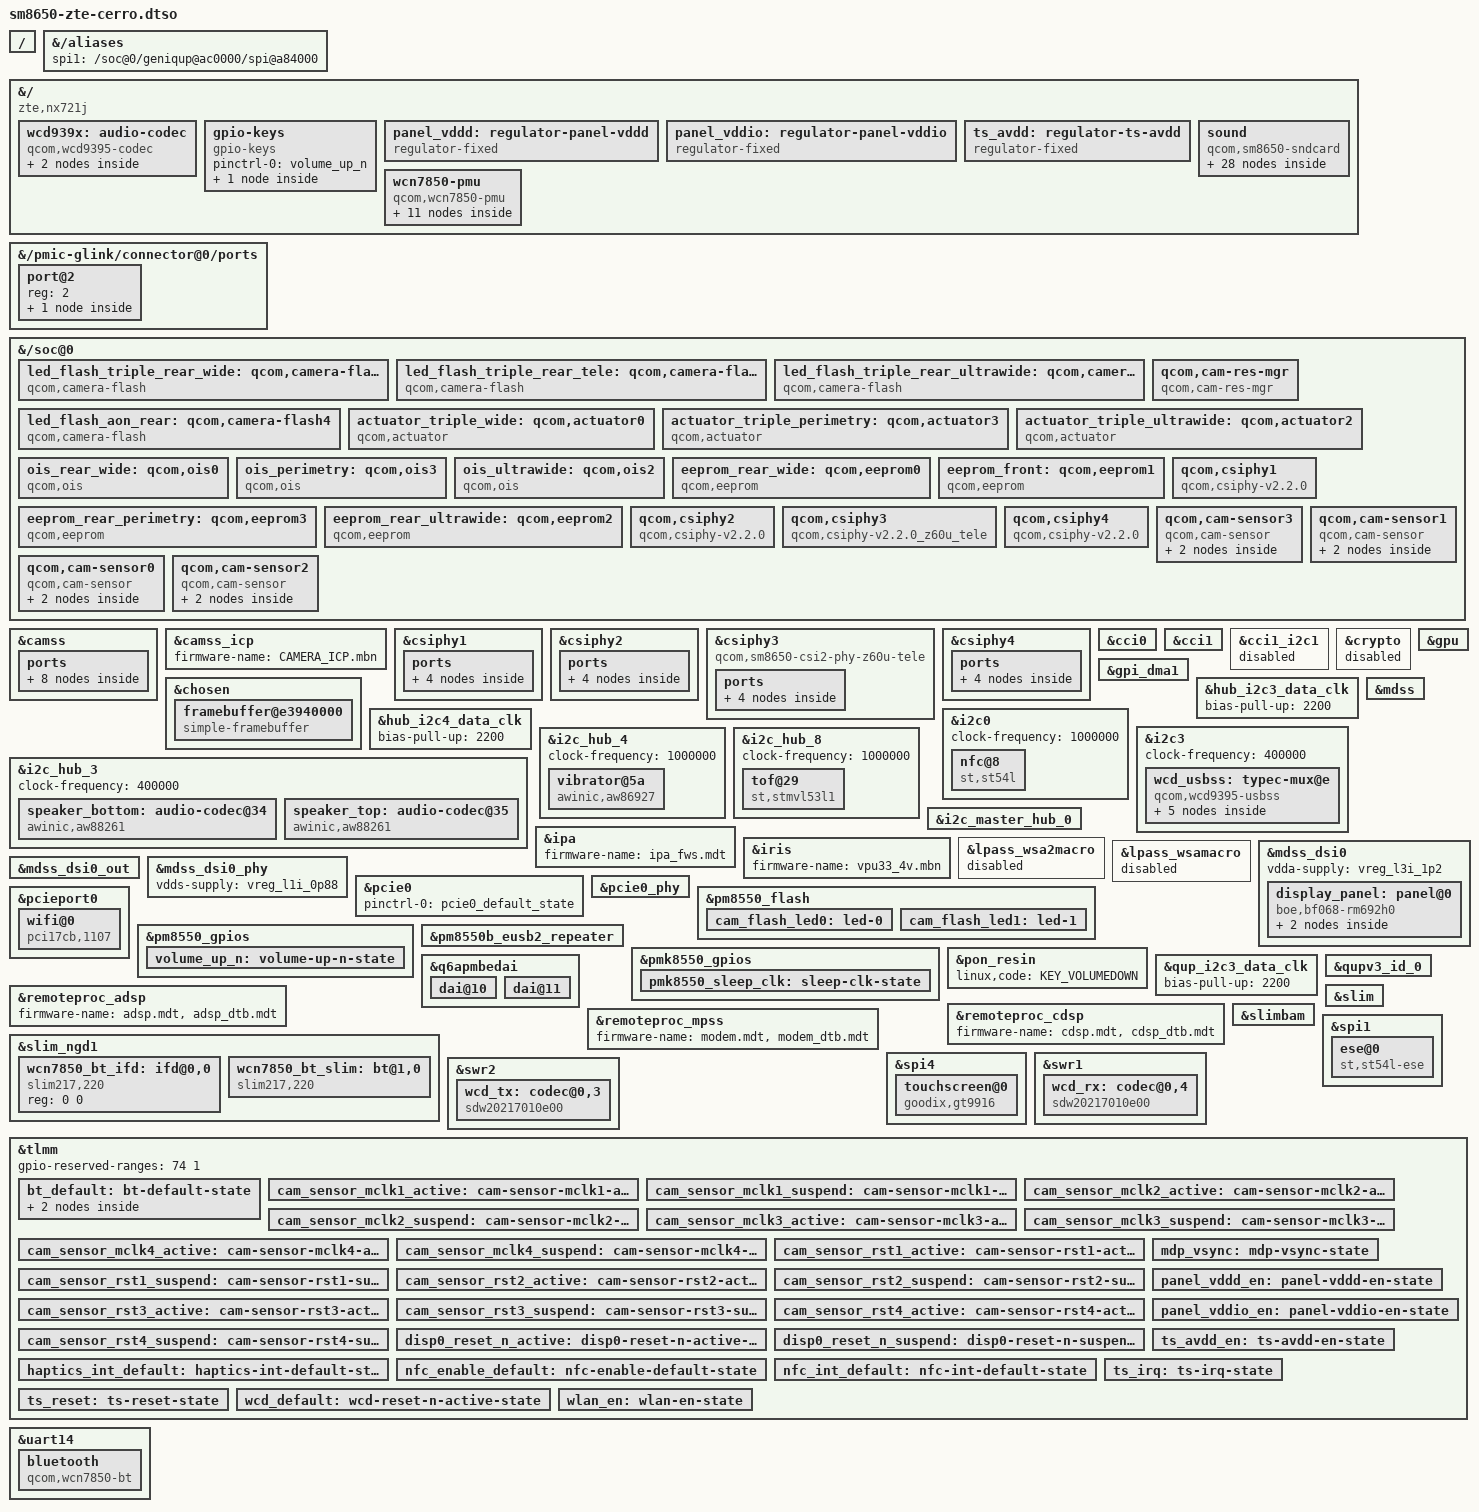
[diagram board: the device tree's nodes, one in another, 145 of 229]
// SPDX-License-Identifier: BSD-3-Clause

/dts-v1/;
/plugin/;

#include <dt-bindings/arm/qcom,ids.h>
#include <dt-bindings/clock/qcom,rpmh.h>
#include <dt-bindings/clock/qcom,sm8650-camcc.h>
#include <dt-bindings/clock/qcom,sm8650-dispcc.h>
#include <dt-bindings/clock/qcom,sm8650-gcc.h>
#include <dt-bindings/gpio/gpio.h>
#include <dt-bindings/input/input.h>
#include <dt-bindings/interrupt-controller/irq.h>
#include <dt-bindings/media/video-interfaces.h>
#include <dt-bindings/leds/common.h>
#include <dt-bindings/msm-camera.h>
#include <dt-bindings/interconnect/qcom,icc.h>
#include <dt-bindings/interconnect/qcom,sm8650-rpmh.h>
#include <dt-bindings/sound/qcom,q6dsp-lpass-ports.h>

/ {
	qcom,msm-id = <QCOM_ID_SM8650 0x20000>, <577 0x20000>;
	qcom,board-id = <8 0>;
};

&{/aliases} {
	spi1 = "/soc@0/geniqup@ac0000/spi@a84000";
};

&{/} {
	model = "ZTE nubia Z60 Ultra";
	compatible = "zte,nx721j", "qcom,sm8650";
	chassis-type = "handset";

	wcd939x: audio-codec {
		compatible = "qcom,wcd9395-codec", "qcom,wcd9390-codec";

		pinctrl-0 = <&wcd_default>;
		pinctrl-names = "default";

		qcom,micbias1-microvolt = <1800000>;
		qcom,micbias2-microvolt = <1800000>;
		qcom,micbias3-microvolt = <1800000>;
		qcom,micbias4-microvolt = <1800000>;
		qcom,mbhc-buttons-vthreshold-microvolt = <100000 200000 400000 500000
							  500000 500000 500000 500000>;
		qcom,mbhc-headset-vthreshold-microvolt = <1700000>;
		qcom,mbhc-headphone-vthreshold-microvolt = <50000>;
		qcom,hphl-jack-type-normally-closed;
		qcom,ground-jack-type-normally-closed;
		qcom,rx-device = <&wcd_rx>;
		qcom,tx-device = <&wcd_tx>;

		reset-gpios = <&tlmm 107 GPIO_ACTIVE_LOW>;

		vdd-buck-supply = <&vreg_l15b_1p8>;
		vdd-rxtx-supply = <&vreg_l15b_1p8>;
		vdd-io-supply = <&vreg_l15b_1p8>;
		vdd-mic-bias-supply = <&vreg_bob1>;
		vdd-px-supply = <&vreg_l3c_1p2>;

		#sound-dai-cells = <1>;

		mode-switch;
		orientation-switch;

		port {
			wcd_codec_headset_in: endpoint {
				remote-endpoint = <&wcd_usbss_headset_out>;
			};
		};
	};

	gpio-keys {
		compatible = "gpio-keys";

		pinctrl-0 = <&volume_up_n>;
		pinctrl-names = "default";

		key-volume-up {
			label = "Volume Up";
			linux,code = <KEY_VOLUMEUP>;
			gpios = <&pm8550_gpios 6 GPIO_ACTIVE_LOW>;
			debounce-interval = <15>;
			linux,can-disable;
			wakeup-source;
		};
	};

	panel_vddd: regulator-panel-vddd {
		compatible = "regulator-fixed";

		regulator-name = "panel_vddd";
		regulator-min-microvolt = <1200000>;
		regulator-max-microvolt = <1200000>;

		gpio = <&tlmm 125 GPIO_ACTIVE_HIGH>;
		enable-active-high;
		regulator-boot-on;

		pinctrl-0 = <&panel_vddd_en>;
		pinctrl-names = "default";
	};

	panel_vddio: regulator-panel-vddio {
		compatible = "regulator-fixed";

		regulator-name = "panel_vddio";
		regulator-min-microvolt = <1800000>;
		regulator-max-microvolt = <1800000>;

		gpio = <&tlmm 14 GPIO_ACTIVE_HIGH>;
		enable-active-high;
		regulator-boot-on;

		vin-supply = <&vreg_l12b_1p8>;

		pinctrl-0 = <&panel_vddio_en>;
		pinctrl-names = "default";
	};

	ts_avdd: regulator-ts-avdd {
		compatible = "regulator-fixed";

		regulator-name = "ts_avdd";

		gpio = <&tlmm 28 GPIO_ACTIVE_HIGH>;
		enable-active-high;

		pinctrl-0 = <&ts_avdd_en>;
		pinctrl-names = "default";
	};

	sound {
		compatible = "qcom,sm8650-sndcard", "qcom,sm8450-sndcard";
		model = "SM8650-CERRO";
		audio-routing = "IN1_HPHL", "HPHL_OUT",
				"IN2_HPHR", "HPHR_OUT",
				"AMIC1", "MIC BIAS1",
				"AMIC2", "MIC BIAS2",
				"AMIC3", "MIC BIAS3",
				"AMIC4", "MIC BIAS3",
				"AMIC5", "MIC BIAS4",
				"TX SWR_INPUT0", "ADC1_OUTPUT",
				"TX SWR_INPUT1", "ADC2_OUTPUT",
				"TX SWR_INPUT2", "ADC3_OUTPUT",
				"TX SWR_INPUT3", "ADC4_OUTPUT",
				"VA SWR_MIC0", "ADC1_OUTPUT",
				"VA SWR_MIC1", "ADC2_OUTPUT",
				"VA SWR_MIC2", "ADC3_OUTPUT",
				"VA SWR_MIC3", "ADC4_OUTPUT";

		pinctrl-0 = <&i2s0_default_state>;
		pinctrl-names = "default";

		speaker-playback-dai-link {
			link-name = "Speaker Playback";

			cpu {
				sound-dai = <&q6apmbedai PRIMARY_MI2S_RX>;
			};

			codec {
				sound-dai = <&speaker_top>, <&speaker_bottom>;
			};

			platform {
				sound-dai = <&q6apm>;
			};
		};

		speaker-feedback-dai-link {
			link-name = "Speaker Feedback";

			cpu {
				sound-dai = <&q6apmbedai PRIMARY_MI2S_TX>;
			};

			codec {
				sound-dai = <&speaker_top>, <&speaker_bottom>;
			};

			platform {
				sound-dai = <&q6apm>;
			};
		};

		wcd-playback-dai-link {
			link-name = "WCD Playback";

			cpu {
				sound-dai = <&q6apmbedai RX_CODEC_DMA_RX_0>;
			};

			codec {
				sound-dai = <&wcd939x 0>, <&swr1 0>, <&lpass_rxmacro 0>;
			};

			platform {
				sound-dai = <&q6apm>;
			};
		};

		wcd-capture-dai-link {
			link-name = "WCD Capture";

			cpu {
				sound-dai = <&q6apmbedai TX_CODEC_DMA_TX_3>;
			};

			codec {
				sound-dai = <&wcd939x 1>, <&swr2 1>, <&lpass_txmacro 0>;
			};

			platform {
				sound-dai = <&q6apm>;
			};
		};

		bt-playback-dai-link {
			link-name = "BT Playback";

			cpu {
				sound-dai = <&q6apmbedai SLIMBUS_6_RX>;
			};

			codec {
				sound-dai = <&wcn7850_bt_slim 0>;
			};

			platform {
				sound-dai = <&q6apm>;
			};
		};

		bt-capture-dai-link {
			link-name = "BT Capture";

			cpu {
				sound-dai = <&q6apmbedai SLIMBUS_6_TX>;
			};

			codec {
				sound-dai = <&wcn7850_bt_slim 1>;
			};

			platform {
				sound-dai = <&q6apm>;
			};
		};

		va-capture-dai-link {
			link-name = "VA Capture";

			cpu {
				sound-dai = <&q6apmbedai VA_CODEC_DMA_TX_0>;
			};

			codec {
				sound-dai = <&wcd939x 1>, <&swr2 1>, <&lpass_vamacro 0>;
			};

			platform {
				sound-dai = <&q6apm>;
			};
		};
	};

	wcn7850-pmu {
		compatible = "qcom,wcn7850-pmu";

		pinctrl-0 = <&wlan_en>, <&bt_default>, <&pmk8550_sleep_clk>;
		pinctrl-names = "default";

		wlan-enable-gpios = <&tlmm 16 GPIO_ACTIVE_HIGH>;
		bt-enable-gpios = <&tlmm 17 GPIO_ACTIVE_HIGH>;

		vdd-supply = <&vreg_s4i_0p85>;
		vddio-supply = <&vreg_l15b_1p8>;
		vddio1p2-supply = <&vreg_l3c_1p2>;
		vddaon-supply = <&vreg_s2c_0p8>;
		vdddig-supply = <&vreg_s3c_0p9>;
		vddrfa1p2-supply = <&vreg_s1c_1p2>;
		vddrfa1p8-supply = <&vreg_s6c_1p8>;

		clocks = <&rpmhcc RPMH_RF_CLK1>;

		regulators {
			vreg_pmu_rfa_cmn: ldo0 {
				regulator-name = "vreg_pmu_rfa_cmn";
			};

			vreg_pmu_aon_0p59: ldo1 {
				regulator-name = "vreg_pmu_aon_0p59";
			};

			vreg_pmu_wlcx_0p8: ldo2 {
				regulator-name = "vreg_pmu_wlcx_0p8";
			};

			vreg_pmu_wlmx_0p85: ldo3 {
				regulator-name = "vreg_pmu_wlmx_0p85";
			};

			vreg_pmu_btcmx_0p85: ldo4 {
				regulator-name = "vreg_pmu_btcmx_0p85";
			};

			vreg_pmu_rfa_0p8: ldo5 {
				regulator-name = "vreg_pmu_rfa_0p8";
			};

			vreg_pmu_rfa_1p2: ldo6 {
				regulator-name = "vreg_pmu_rfa_1p2";
			};

			vreg_pmu_rfa_1p8: ldo7 {
				regulator-name = "vreg_pmu_rfa_1p8";
			};

			vreg_pmu_pcie_0p9: ldo8 {
				regulator-name = "vreg_pmu_pcie_0p9";
			};

			vreg_pmu_pcie_1p8: ldo9 {
				regulator-name = "vreg_pmu_pcie_1p8";
			};
		};
	};
};

&{/pmic-glink/connector@0/ports} {
	#address-cells = <1>;
	#size-cells = <0>;

	port@2 {
		reg = <2>;

		pmic_glink_sbu: endpoint {
			remote-endpoint = <&wcd_usbss_sbu_mux>;
		};
	};
};

&{/soc@0} {
	led_flash_triple_rear_wide: qcom,camera-flash1 {
		cell-index = <1>;
		compatible = "qcom,camera-flash";
		flash-source = <&cam_flash_led0 &cam_flash_led1>;
		torch-source = <&cam_flash_led0 &cam_flash_led1>;
		leds = <&cam_flash_led0 &cam_flash_led1
			&cam_flash_led0 &cam_flash_led1>;
		led-names = "flash0", "flash1", "torch0", "torch1";
	};

	led_flash_triple_rear_tele: qcom,camera-flash2 {
		cell-index = <2>;
		compatible = "qcom,camera-flash";
		flash-source = <&cam_flash_led0 &cam_flash_led1>;
		torch-source = <&cam_flash_led0 &cam_flash_led1>;
		leds = <&cam_flash_led0 &cam_flash_led1
			&cam_flash_led0 &cam_flash_led1>;
		led-names = "flash0", "flash1", "torch0", "torch1";
	};

	led_flash_triple_rear_ultrawide: qcom,camera-flash3 {
		cell-index = <3>;
		compatible = "qcom,camera-flash";
		flash-source = <&cam_flash_led0 &cam_flash_led1>;
		torch-source = <&cam_flash_led0 &cam_flash_led1>;
		leds = <&cam_flash_led0 &cam_flash_led1
			&cam_flash_led0 &cam_flash_led1>;
		led-names = "flash0", "flash1", "torch0", "torch1";
	};

	led_flash_aon_rear: qcom,camera-flash4 {
		cell-index = <4>;
		compatible = "qcom,camera-flash";
		flash-source = <&cam_flash_led0 &cam_flash_led1>;
		torch-source = <&cam_flash_led0 &cam_flash_led1>;
		leds = <&cam_flash_led0 &cam_flash_led1
			&cam_flash_led0 &cam_flash_led1>;
		led-names = "flash0", "flash1", "torch0", "torch1";
	};

	qcom,cam-res-mgr {
		compatible = "qcom,cam-res-mgr";
	};

	actuator_triple_wide: qcom,actuator0 {
		cell-index = <0>;
		compatible = "qcom,actuator";
		cci-master = <CCI_MASTER_1>;
		cci-i2c-bus = <&cci0_i2c1>;
		cam_vaf-supply = <&vreg_l3m_2p8>;
		regulator-names = "cam_vaf";
		rgltr-cntrl-support;
		rgltr-min-voltage = <2704000>;
		rgltr-max-voltage = <3000000>;
		rgltr-load-current = <103000>;
	};

	actuator_triple_perimetry: qcom,actuator3 {
		cell-index = <3>;
		compatible = "qcom,actuator";
		cci-master = <CCI_MASTER_0>;
		cci-i2c-bus = <&cci0_i2c0>;
		cam_vaf-supply = <&vreg_l4m_2p8>;
		cam_v_custom1-supply = <&vreg_l6m_2p8>;
		regulator-names = "cam_vaf", "cam_v_custom1";
		rgltr-cntrl-support;
		rgltr-min-voltage = <2800000 2800000>;
		rgltr-max-voltage = <2800000 2800000>;
		rgltr-load-current = <103000 103000>;
	};

	actuator_triple_ultrawide: qcom,actuator2 {
		cell-index = <2>;
		compatible = "qcom,actuator";
		cci-master = <CCI_MASTER_0>;
		cci-i2c-bus = <&cci1_i2c0>;
		cam_vaf-supply = <&vreg_bob2>;
		regulator-names = "cam_vaf";
		rgltr-cntrl-support;
		rgltr-min-voltage = <2704000>;
		rgltr-max-voltage = <3000000>;
		rgltr-load-current = <103000>;
	};

	ois_rear_wide: qcom,ois0 {
		cell-index = <0>;
		compatible = "qcom,ois";
		cci-master = <CCI_MASTER_1>;
		cci-i2c-bus = <&cci0_i2c1>;
		cam_vaf-supply = <&vreg_l3m_2p8>;
		cam_v_custom1-supply = <&vreg_l7m_2p96>;
		regulator-names = "cam_vaf", "cam_v_custom1";
		rgltr-cntrl-support;
		rgltr-min-voltage = <2704000 2960000>;
		rgltr-max-voltage = <3000000 2960000>;
		rgltr-load-current = <103000 90000>;
	};

	ois_perimetry: qcom,ois3 {
		cell-index = <3>;
		compatible = "qcom,ois";
		cci-master = <CCI_MASTER_0>;
		cci-i2c-bus = <&cci0_i2c0>;
		cam_vaf-supply = <&vreg_l4m_2p8>;
		cam_v_custom1-supply = <&vreg_l6m_2p8>;
		regulator-names = "cam_vaf", "cam_v_custom1";
		rgltr-cntrl-support;
		rgltr-min-voltage = <2800000 2800000>;
		rgltr-max-voltage = <2800000 2800000>;
		rgltr-load-current = <119000 119000>;
	};

	ois_ultrawide: qcom,ois2 {
		cell-index = <2>;
		compatible = "qcom,ois";
		cci-master = <CCI_MASTER_0>;
		cci-i2c-bus = <&cci1_i2c0>;
		cam_vio-supply = <&vreg_l5m_1p8>;
		cam_vaf-supply = <&vreg_bob2>;
		regulator-names = "cam_vio", "cam_vaf";
		rgltr-cntrl-support;
		rgltr-min-voltage = <1800000 2704000>;
		rgltr-max-voltage = <1800000 3000000>;
		rgltr-load-current = <4000 103000>;
	};

	eeprom_rear_wide: qcom,eeprom0 {
		cell-index = <0>;
		compatible = "qcom,eeprom";
		cam_vio-supply = <&vreg_l5m_1p8>;
		cam_vdig-supply = <&vreg_l1m_1p1>;
		cam_vaf-supply = <&vreg_l3m_2p8>;
		cam_v_custom1-supply = <&vreg_l7m_2p96>;
		regulator-names = "cam_vio", "cam_vdig", "cam_vaf", "cam_v_custom1";
		rgltr-cntrl-support;
		rgltr-min-voltage = <1800000 1104000 2704000 2960000>;
		rgltr-max-voltage = <1800000 1104000 3000000 2960000>;
		rgltr-load-current = <3500 140000 103000 90000>;
		gpio-no-mux = <0>;
		pinctrl-names = "cam_default", "cam_suspend";
		pinctrl-0 = <&cam_sensor_mclk1_active
			     &cam_sensor_rst1_active>;
		pinctrl-1 = <&cam_sensor_mclk1_suspend
			     &cam_sensor_rst1_suspend>;
		gpios = <&tlmm 101 0>,
			<&tlmm 15 0>,
			<&tlmm 13 0>;
		gpio-reset = <1>;
		gpio-custom1 = <2>;
		gpio-req-tbl-num = <0 1 2>;
		gpio-req-tbl-flags = <1 0 0>;
		gpio-req-tbl-label = "CAMIF_MCLK1",
				     "CAM_RESET1",
				     "CAM_VANA1";
		cci-master = <CCI_MASTER_1>;
		cci-i2c-bus = <&cci0_i2c1>;
		clocks = <&camcc CAM_CC_MCLK1_CLK>;
		clock-names = "cam_clk";
		clock-cntl-level = "nominal";
		clock-rates = <24000000>;
		power-domains = <&camcc CAM_CC_TITAN_TOP_GDSC>;
	};

	eeprom_front: qcom,eeprom1 {
		cell-index = <1>;
		compatible = "qcom,eeprom";
		cam_vio-supply = <&vreg_l5m_1p8>;
		regulator-names = "cam_vio";
		rgltr-cntrl-support;
		rgltr-min-voltage = <1800000>;
		rgltr-max-voltage = <1800000>;
		rgltr-load-current = <6000>;
		gpio-no-mux = <0>;
		pinctrl-names = "cam_default", "cam_suspend";
		pinctrl-0 = <&cam_sensor_mclk4_active
			     &cam_sensor_rst4_active>;
		pinctrl-1 = <&cam_sensor_mclk4_suspend
			     &cam_sensor_rst4_suspend>;
		gpios = <&tlmm 104 0>,
			<&tlmm 7 0>,
			<&tlmm 58 0>;
		gpio-reset = <1>;
		gpio-custom1 = <2>;
		gpio-req-tbl-num = <0 1 2>;
		gpio-req-tbl-flags = <1 0 0>;
		gpio-req-tbl-label = "CAMIF_MCLK4",
				     "CAM_RESET4",
				     "CAM_VANA4";
		cci-master = <CCI_MASTER_0>;
		cci-i2c-bus = <&cci0_i2c0>;
		clocks = <&camcc CAM_CC_MCLK4_CLK>;
		clock-names = "cam_clk";
		clock-cntl-level = "nominal";
		clock-rates = <24000000>;
		power-domains = <&camcc CAM_CC_TITAN_TOP_GDSC>;
	};

	eeprom_rear_perimetry: qcom,eeprom3 {
		cell-index = <3>;
		compatible = "qcom,eeprom";
		cam_vio-supply = <&vreg_l5m_1p8>;
		cam_vaf-supply = <&vreg_l4m_2p8>;
		cam_v_custom1-supply = <&vreg_l6m_2p8>;
		regulator-names = "cam_vio", "cam_vaf", "cam_v_custom1";
		rgltr-cntrl-support;
		rgltr-min-voltage = <1800000 2704000 2800000>;
		rgltr-max-voltage = <1800000 3000000 2800000>;
		rgltr-load-current = <6000 103000 119000>;
		gpio-no-mux = <0>;
		pinctrl-names = "cam_default", "cam_suspend";
		pinctrl-0 = <&cam_sensor_mclk3_active
			     &cam_sensor_rst3_active>;
		pinctrl-1 = <&cam_sensor_mclk3_suspend
			     &cam_sensor_rst3_suspend>;
		gpios = <&tlmm 103 0>,
			<&tlmm 109 0>,
			<&tlmm 6 0>;
		gpio-reset = <1>;
		gpio-custom1 = <2>;
		gpio-req-tbl-num = <0 1 2>;
		gpio-req-tbl-flags = <1 0 0>;
		gpio-req-tbl-label = "CAMIF_MCLK3",
				     "CAM_RESET3",
				     "CAM_VANA3";
		cci-master = <CCI_MASTER_0>;
		cci-i2c-bus = <&cci0_i2c0>;
		clocks = <&camcc CAM_CC_MCLK3_CLK>;
		clock-names = "cam_clk";
		clock-cntl-level = "nominal";
		clock-rates = <24000000>;
		power-domains = <&camcc CAM_CC_TITAN_TOP_GDSC>;
	};

	eeprom_rear_ultrawide: qcom,eeprom2 {
		cell-index = <2>;
		compatible = "qcom,eeprom";
		cam_vio-supply = <&vreg_l5m_1p8>;
		regulator-names = "cam_vio";
		rgltr-cntrl-support;
		rgltr-min-voltage = <1800000>;
		rgltr-max-voltage = <1800000>;
		rgltr-load-current = <3500>;
		gpio-no-mux = <0>;
		pinctrl-names = "cam_default", "cam_suspend";
		pinctrl-0 = <&cam_sensor_mclk2_active
			     &cam_sensor_rst2_active>;
		pinctrl-1 = <&cam_sensor_mclk2_suspend
			     &cam_sensor_rst2_suspend>;
		gpios = <&tlmm 102 0>,
			<&tlmm 3 0>,
			<&tlmm 2 0>;
		gpio-reset = <1>;
		gpio-custom1 = <2>;
		gpio-req-tbl-num = <0 1 2>;
		gpio-req-tbl-flags = <1 0 0>;
		gpio-req-tbl-label = "CAMIF_MCLK2",
				     "CAM_RESET2",
				     "CAM_VANA2";
		cci-master = <CCI_MASTER_0>;
		cci-i2c-bus = <&cci1_i2c0>;
		clocks = <&camcc CAM_CC_MCLK2_CLK>;
		clock-names = "cam_clk";
		clock-cntl-level = "nominal";
		clock-rates = <24000000>;
		power-domains = <&camcc CAM_CC_TITAN_TOP_GDSC>;
	};

	qcom,csiphy1 {
		cell-index = <1>;
		compatible = "qcom,csiphy-v2.2.0", "qcom,csiphy";
		phys = <&csiphy1>;
	};

	qcom,csiphy2 {
		cell-index = <2>;
		compatible = "qcom,csiphy-v2.2.0", "qcom,csiphy";
		phys = <&csiphy2>;
	};

	qcom,csiphy3 {
		cell-index = <3>;
		compatible = "qcom,csiphy-v2.2.0_z60u_tele", "qcom,csiphy";
		phys = <&csiphy3>;
	};

	qcom,csiphy4 {
		cell-index = <4>;
		compatible = "qcom,csiphy-v2.2.0", "qcom,csiphy";
		phys = <&csiphy4>;
	};

	qcom,cam-sensor3 {
		cell-index = <3>;
		compatible = "qcom,cam-sensor";
		csiphy-sd-index = <3>;
		sensor-position-roll = <90>;
		sensor-position-pitch = <0>;
		sensor-position-yaw = <180>;
		actuator-src = <&actuator_triple_perimetry>;
		eeprom-src = <&eeprom_rear_perimetry>;
		led-flash-src = <&led_flash_triple_rear_tele>;
		ois-src = <&ois_perimetry>;
		cam_vio-supply = <&vreg_l5m_1p8>;
		cam_vaf-supply = <&vreg_l4m_2p8>;
		cam_v_custom1-supply = <&vreg_l6m_2p8>;
		regulator-names = "cam_vio", "cam_vaf", "cam_v_custom1";
		rgltr-cntrl-support;
		rgltr-min-voltage = <1800000 2704000 2800000>;
		rgltr-max-voltage = <1800000 3000000 2800000>;
		rgltr-load-current = <6000 103000 119000>;
		gpio-no-mux = <0>;
		pinctrl-names = "cam_default", "cam_suspend";
		pinctrl-0 = <&cam_sensor_mclk3_active
			     &cam_sensor_rst3_active>;
		pinctrl-1 = <&cam_sensor_mclk3_suspend
			     &cam_sensor_rst3_suspend>;
		gpios = <&tlmm 103 0>,
			<&tlmm 109 0>,
			<&tlmm 6 0>;
		gpio-reset = <1>;
		gpio-custom1 = <2>;
		gpio-req-tbl-num = <0 1 2>;
		gpio-req-tbl-flags = <1 0 0>;
		gpio-req-tbl-label = "CAMIF_MCLK3",
				     "CAM_RESET3",
				     "CAM_VANA3";
		cci-master = <CCI_MASTER_0>;
		cci-i2c-bus = <&cci0_i2c0>;
		clocks = <&camcc CAM_CC_MCLK3_CLK>;
		clock-names = "cam_clk";
		clock-cntl-level = "nominal";
		clock-rates = <24000000>;
		power-domains = <&camcc CAM_CC_TITAN_TOP_GDSC>;
		zte-tof-enable;

		port {
			sensor3_ep: endpoint {
				remote-endpoint = <&csiphy3_in>;
			};
		};
	};

	qcom,cam-sensor1 {
		cell-index = <1>;
		compatible = "qcom,cam-sensor";
		csiphy-sd-index = <4>;
		sensor-position-roll = <270>;
		sensor-position-pitch = <0>;
		sensor-position-yaw = <0>;
		eeprom-src = <&eeprom_front>;
		cam_vio-supply = <&vreg_l5m_1p8>;
		regulator-names = "cam_vio";
		rgltr-cntrl-support;
		rgltr-min-voltage = <1800000>;
		rgltr-max-voltage = <1800000>;
		rgltr-load-current = <6000>;
		gpio-no-mux = <0>;
		pinctrl-names = "cam_default", "cam_suspend";
		pinctrl-0 = <&cam_sensor_mclk4_active
			     &cam_sensor_rst4_active>;
		pinctrl-1 = <&cam_sensor_mclk4_suspend
			     &cam_sensor_rst4_suspend>;
		gpios = <&tlmm 104 0>,
			<&tlmm 7 0>,
			<&tlmm 58 0>;
		gpio-reset = <1>;
		gpio-custom1 = <2>;
		gpio-req-tbl-num = <0 1 2>;
		gpio-req-tbl-flags = <1 0 0>;
		gpio-req-tbl-label = "CAMIF_MCLK4",
				     "CAM_RESET4",
				     "CAM_VANA4";
		cci-master = <CCI_MASTER_0>;
		cci-i2c-bus = <&cci0_i2c0>;
		clocks = <&camcc CAM_CC_MCLK4_CLK>;
		clock-names = "cam_clk";
		clock-cntl-level = "nominal";
		clock-rates = <24000000>;
		power-domains = <&camcc CAM_CC_TITAN_TOP_GDSC>;
		zte-tof-enable;

		port {
			sensor1_ep: endpoint {
				remote-endpoint = <&csiphy4_in>;
			};
		};
	};

	qcom,cam-sensor0 {
		cell-index = <0>;
		compatible = "qcom,cam-sensor";
		csiphy-sd-index = <1>;
		sensor-position-roll = <90>;
		sensor-position-pitch = <0>;
		sensor-position-yaw = <180>;
		actuator-src = <&actuator_triple_wide>;
		ois-src = <&ois_rear_wide>;
		eeprom-src = <&eeprom_rear_wide>;
		led-flash-src = <&led_flash_triple_rear_wide>;
		cam_vio-supply = <&vreg_l5m_1p8>;
		cam_vdig-supply = <&vreg_l1m_1p1>;
		cam_vaf-supply = <&vreg_l3m_2p8>;
		cam_v_custom1-supply = <&vreg_l7m_2p96>;
		regulator-names = "cam_vio", "cam_vdig", "cam_vaf", "cam_v_custom1";
		rgltr-cntrl-support;
		rgltr-min-voltage = <1800000 1104000 2704000 2960000>;
		rgltr-max-voltage = <1800000 1104000 3000000 2960000>;
		rgltr-load-current = <3500 140000 103000 90000>;
		gpio-no-mux = <0>;
		pinctrl-names = "cam_default", "cam_suspend";
		pinctrl-0 = <&cam_sensor_mclk1_active
			     &cam_sensor_rst1_active>;
		pinctrl-1 = <&cam_sensor_mclk1_suspend
			     &cam_sensor_rst1_suspend>;
		gpios = <&tlmm 101 0>,
			<&tlmm 15 0>,
			<&tlmm 13 0>;
		gpio-reset = <1>;
		gpio-custom1 = <2>;
		gpio-req-tbl-num = <0 1 2>;
		gpio-req-tbl-flags = <1 0 0>;
		gpio-req-tbl-label = "CAMIF_MCLK1",
				     "CAM_RESET1",
				     "CAM_VANA1";
		cci-master = <CCI_MASTER_1>;
		cci-i2c-bus = <&cci0_i2c1>;
		clocks = <&camcc CAM_CC_MCLK1_CLK>;
		clock-names = "cam_clk";
		clock-cntl-level = "nominal";
		clock-rates = <24000000>;
		power-domains = <&camcc CAM_CC_TITAN_TOP_GDSC>;
		zte-tof-enable;

		port {
			sensor0_ep: endpoint {
				remote-endpoint = <&csiphy1_in>;
			};
		};
	};

	qcom,cam-sensor2 {
		cell-index = <2>;
		compatible = "qcom,cam-sensor";
		csiphy-sd-index = <2>;
		sensor-position-roll = <90>;
		sensor-position-pitch = <0>;
		sensor-position-yaw = <180>;
		actuator-src = <&actuator_triple_ultrawide>;
		eeprom-src = <&eeprom_rear_ultrawide>;
		led-flash-src = <&led_flash_triple_rear_ultrawide>;
		ois-src = <&ois_ultrawide>;
		cam_vio-supply = <&vreg_l5m_1p8>;
		cam_vdig-supply = <&vreg_l2m_1p056>;
		regulator-names = "cam_vio", "cam_vdig";
		rgltr-cntrl-support;
		rgltr-min-voltage = <1800000 1056000>;
		rgltr-max-voltage = <1800000 1056000>;
		rgltr-load-current = <3500 140000>;
		gpio-no-mux = <0>;
		pinctrl-names = "cam_default", "cam_suspend";
		pinctrl-0 = <&cam_sensor_mclk2_active
			     &cam_sensor_rst2_active>;
		pinctrl-1 = <&cam_sensor_mclk2_suspend
			     &cam_sensor_rst2_suspend>;
		gpios = <&tlmm 102 0>,
			<&tlmm 3 0>,
			<&tlmm 2 0>;
		gpio-reset = <1>;
		gpio-custom1 = <2>;
		gpio-req-tbl-num = <0 1 2>;
		gpio-req-tbl-flags = <1 0 0>;
		gpio-req-tbl-label = "CAMIF_MCLK2",
				     "CAM_RESET2",
				     "CAM_VANA2";
		cci-master = <CCI_MASTER_0>;
		cci-i2c-bus = <&cci1_i2c0>;
		clocks = <&camcc CAM_CC_MCLK2_CLK>;
		clock-names = "cam_clk";
		clock-cntl-level = "nominal";
		clock-rates = <24000000>;
		power-domains = <&camcc CAM_CC_TITAN_TOP_GDSC>;
		zte-tof-enable;

		port {
			sensor2_ep: endpoint {
				remote-endpoint = <&csiphy2_in>;
			};
		};
	};
};

&camss {
	vdd-csiphy01-0p9-supply = <&vreg_l2i_0p88>;
	vdd-csiphy01-1p2-supply = <&vreg_l3i_1p2>;
	vdd-csiphy24-0p9-supply = <&vreg_l2i_0p88>;
	vdd-csiphy24-1p2-supply = <&vreg_l3i_1p2>;
	vdd-csiphy35-0p9-supply = <&vreg_l2i_0p88>;
	vdd-csiphy35-1p2-supply = <&vreg_l3i_1p2>;

	status = "okay";

	ports {
		#address-cells = <1>;
		#size-cells = <0>;

		port@1 {
			camss_ep1: endpoint {
				bus-type = <MEDIA_BUS_TYPE_CSI2_CPHY>;
				data-lanes = <1 2 3>;
				remote-endpoint = <&csiphy1_out>;
			};
		};

		port@2 {
			camss_ep2: endpoint {
				bus-type = <MEDIA_BUS_TYPE_CSI2_CPHY>;
				data-lanes = <1 2 3>;
				remote-endpoint = <&csiphy2_out>;
			};
		};

		port@3 {
			camss_ep3: endpoint {
				bus-type = <MEDIA_BUS_TYPE_CSI2_CPHY>;
				data-lanes = <1 2 3>;
				remote-endpoint = <&csiphy3_out>;
			};
		};

		port@4 {
			camss_ep4: endpoint {
				bus-type = <MEDIA_BUS_TYPE_CSI2_DPHY>;
				data-lanes = <1 2 3 4>;
				remote-endpoint = <&csiphy4_out>;
			};
		};
	};
};

&camss_icp {
	firmware-name = "CAMERA_ICP.mbn";

	status = "okay";
};

&csiphy1 {
	vdda-phy-supply = <&vreg_l2i_0p88>;
	vdda-pll-supply = <&vreg_l3i_1p2>;

	status = "okay";

	ports {
		port@0 {
			csiphy1_in: endpoint {
				bus-type = <MEDIA_BUS_TYPE_CSI2_CPHY>;
				data-lanes = <1 2 3>;
				remote-endpoint = <&sensor0_ep>;
			};
		};

		port@1 {
			csiphy1_out: endpoint {
				remote-endpoint = <&camss_ep1>;
			};
		};
	};
};

&csiphy2 {
	vdda-phy-supply = <&vreg_l2i_0p88>;
	vdda-pll-supply = <&vreg_l3i_1p2>;

	status = "okay";

	ports {
		port@0 {
			csiphy2_in: endpoint {
				bus-type = <MEDIA_BUS_TYPE_CSI2_CPHY>;
				data-lanes = <1 2 3>;
				remote-endpoint = <&sensor2_ep>;
			};
		};

		port@1 {
			csiphy2_out: endpoint {
				remote-endpoint = <&camss_ep2>;
			};
		};
	};
};

&csiphy3 {
	compatible = "qcom,sm8650-csi2-phy-z60u-tele";
	vdda-phy-supply = <&vreg_l2i_0p88>;
	vdda-pll-supply = <&vreg_l3i_1p2>;

	status = "okay";

	ports {
		port@0 {
			csiphy3_in: endpoint {
				bus-type = <MEDIA_BUS_TYPE_CSI2_CPHY>;
				data-lanes = <1 2 3>;
				remote-endpoint = <&sensor3_ep>;
			};
		};

		port@1 {
			csiphy3_out: endpoint {
				remote-endpoint = <&camss_ep3>;
			};
		};
	};
};

&csiphy4 {
	vdda-phy-supply = <&vreg_l2i_0p88>;
	vdda-pll-supply = <&vreg_l3i_1p2>;

	status = "okay";

	ports {
		port@0 {
			csiphy4_in: endpoint {
				bus-type = <MEDIA_BUS_TYPE_CSI2_DPHY>;
				data-lanes = <1 2 3 4>;
				remote-endpoint = <&sensor1_ep>;
			};
		};

		port@1 {
			csiphy4_out: endpoint {
				remote-endpoint = <&camss_ep4>;
			};
		};
	};
};

&cci0 {
	status = "okay";
};

&cci1 {
	/* Master 1 pins carry the main camera VANA enable (gpio13) */
	pinctrl-0 = <&cci1_0_default>;
	pinctrl-1 = <&cci1_0_sleep>;

	status = "okay";
};

&cci1_i2c1 {
	status = "disabled";
};

&chosen {
	#address-cells = <2>;
	#size-cells = <2>;

	framebuffer@e3940000 {
		compatible = "simple-framebuffer";
		reg = <0x0 0xe3940000 0x0 0x2b00000>;
		width = <1116>;
		height = <2480>;
		stride = <(1116 * 4)>;
		format = "a8b8g8r8";
		interconnects = <&mmss_noc MASTER_MDP QCOM_ICC_TAG_ALWAYS
				 &mc_virt SLAVE_EBI1 QCOM_ICC_TAG_ALWAYS>;
		clocks = <&gcc GCC_DISP_HF_AXI_CLK>;
		power-domains = <&dispcc MDSS_GDSC>;

		vci-supply = <&vreg_l13b_3p0>;
		vdd-supply = <&vreg_l11b_1p2>;
		vddd-supply = <&panel_vddd>;
		vddio-supply = <&panel_vddio>;
	};
};

&crypto {
	status = "disabled";
};

&gpi_dma1 {
	status = "okay";
};

&gpu {
	status = "okay";
};

&hub_i2c3_data_clk {
	/* Use internal I2C pull-up */
	bias-pull-up = <2200>;
};

&hub_i2c4_data_clk {
	/* Use internal I2C pull-up */
	bias-pull-up = <2200>;
};

&i2c0 {
	#address-cells = <1>;
	#size-cells = <0>;

	clock-frequency = <1000000>;

	status = "okay";

	nfc@8 {
		compatible = "st,st54l", "st,st21nfcd";
		reg = <0x08>;

		interrupts-extended = <&tlmm 75 IRQ_TYPE_LEVEL_HIGH>;
		reset-gpios = <&tlmm 34 GPIO_ACTIVE_HIGH>;
		ese-power-gpios = <&tlmm 46 GPIO_ACTIVE_HIGH>;

		pinctrl-0 = <&nfc_int_default>, <&nfc_enable_default>;
		pinctrl-names = "default";

		wakeup-source;
	};
};

&i2c3 {
	#address-cells = <1>;
	#size-cells = <0>;

	clock-frequency = <400000>;

	status = "okay";

	wcd_usbss: typec-mux@e {
		compatible = "qcom,wcd9395-usbss", "qcom,wcd9390-usbss";
		reg = <0xe>;

		vdd-supply = <&vreg_l15b_1p8>;

		mode-switch;
		orientation-switch;

		ports {
			#address-cells = <1>;
			#size-cells = <0>;

			port@0 {
				reg = <0>;

				wcd_usbss_sbu_mux: endpoint {
					remote-endpoint = <&pmic_glink_sbu>;
				};
			};

			port@1 {
				reg = <1>;

				wcd_usbss_headset_out: endpoint {
					remote-endpoint = <&wcd_codec_headset_in>;
				};
			};
		};
	};
};

&i2c_hub_3 {
	#address-cells = <1>;
	#size-cells = <0>;

	clock-frequency = <400000>;

	status = "okay";

	/* Bottom speaker */
	speaker_bottom: audio-codec@34 {
		compatible = "awinic,aw88261";
		reg = <0x34>;

		dvdd-supply = <&vreg_l15b_1p8>;
		sound-name-prefix = "Bottom Amp";
		firmware-name = "aw882xx_acf.bin";

		#sound-dai-cells = <0>;

		awinic,audio-channel = <1>;
	};

	/* Top speaker / ear speaker */
	speaker_top: audio-codec@35 {
		compatible = "awinic,aw88261";
		reg = <0x35>;

		dvdd-supply = <&vreg_l15b_1p8>;
		sound-name-prefix = "Top Amp";
		firmware-name = "aw882xx_acf.bin";

		#sound-dai-cells = <0>;

		awinic,audio-channel = <0>;
	};
};

&i2c_hub_4 {
	#address-cells = <1>;
	#size-cells = <0>;

	clock-frequency = <1000000>;

	status = "okay";

	vibrator@5a {
		compatible = "awinic,aw86927";
		reg = <0x5a>;

		interrupts-extended = <&tlmm 163 IRQ_TYPE_EDGE_FALLING>;
		reset-gpios = <&tlmm 120 GPIO_ACTIVE_LOW>;

		pinctrl-0 = <&haptics_int_default>;
		pinctrl-names = "default";
	};
};

&i2c_hub_8 {
	#address-cells = <1>;
	#size-cells = <0>;

	status = "okay";

	clock-frequency = <1000000>;

	tof@29 {
		compatible = "st,stmvl53l1";
		reg = <0x29>;

		xsdn-gpio = <&tlmm 97 0>;
		intr-gpio = <&tlmm 99 0>;
		pwren-gpio = <&tlmm 91 0>;
		boot-reg = <0x29>;
	};
};

&i2c_master_hub_0 {
	status = "okay";
};

&ipa {
	firmware-name = "ipa_fws.mdt";

	status = "okay";
};

&iris {
	firmware-name = "vpu33_4v.mbn";

	status = "okay";
};

&lpass_wsa2macro {
	status = "disabled";
};

&lpass_wsamacro {
	status = "disabled";
};

&mdss {
	resets = <&dispcc DISP_CC_MDSS_CORE_BCR>,
		 <&dispcc DISP_CC_MDSS_CORE_INT2_BCR>,
		 <&dispcc DISP_CC_MDSS_RSCC_BCR>;

	status = "okay";
};

&mdss_dsi0 {
	#address-cells = <1>;
	#size-cells = <0>;

	vdda-supply = <&vreg_l3i_1p2>;

	status = "okay";

	display_panel: panel@0 {
		compatible = "boe,bf068-rm692h0";
		reg = <0>;

		reset-gpios = <&tlmm 133 GPIO_ACTIVE_LOW>;

		vddio-supply = <&panel_vddio>;
		vddd-supply = <&panel_vddd>;
		vdd-supply = <&vreg_l11b_1p2>;
		vci-supply = <&vreg_l13b_3p0>;

		pinctrl-0 = <&disp0_reset_n_active>, <&mdp_vsync>;
		pinctrl-1 = <&disp0_reset_n_suspend>, <&mdp_vsync>;
		pinctrl-names = "default", "sleep";

		width-mm = <71>;
		height-mm = <157>;

		port {
			panel0_in: endpoint {
				remote-endpoint = <&mdss_dsi0_out>;
			};
		};
	};
};

&mdss_dsi0_out {
	remote-endpoint = <&panel0_in>;
	data-lanes = <0 1 2 3>;
};

&mdss_dsi0_phy {
	vdds-supply = <&vreg_l1i_0p88>;

	status = "okay";
};

&pcie0 {
	pinctrl-0 = <&pcie0_default_state>;
	pinctrl-names = "default";

	status = "okay";
};

&pcie0_phy {
	vdda-phy-supply = <&vreg_l1i_0p88>;
	vdda-pll-supply = <&vreg_l3i_1p2>;

	status = "okay";
};

&pcieport0 {
	#address-cells = <3>;
	#size-cells = <2>;

	reset-gpios = <&tlmm 94 GPIO_ACTIVE_LOW>;
	wake-gpios = <&tlmm 96 GPIO_ACTIVE_LOW>;

	wifi@0 {
		compatible = "pci17cb,1107";
		reg = <0x10000 0x0 0x0 0x0 0x0>;

		vddrfacmn-supply = <&vreg_pmu_rfa_cmn>;
		vddaon-supply = <&vreg_pmu_aon_0p59>;
		vddwlcx-supply = <&vreg_pmu_wlcx_0p8>;
		vddwlmx-supply = <&vreg_pmu_wlmx_0p85>;
		vddrfa0p8-supply = <&vreg_pmu_rfa_0p8>;
		vddrfa1p2-supply = <&vreg_pmu_rfa_1p2>;
		vddrfa1p8-supply = <&vreg_pmu_rfa_1p8>;
		vddpcie0p9-supply = <&vreg_pmu_pcie_0p9>;
		vddpcie1p8-supply = <&vreg_pmu_pcie_1p8>;
	};
};

&pm8550_flash {
	status = "okay";

	cam_flash_led0: led-0 {
		function = LED_FUNCTION_FLASH;
		color = <LED_COLOR_ID_WHITE>;
		function-enumerator = <0>;
		led-sources = <1>, <4>;
		led-max-microamp = <500000>;
		flash-max-microamp = <1500000>;
		flash-max-timeout-us = <1280000>;
	};

	cam_flash_led1: led-1 {
		function = LED_FUNCTION_FLASH;
		color = <LED_COLOR_ID_WHITE>;
		function-enumerator = <1>;
		led-sources = <2>, <3>;
		led-max-microamp = <500000>;
		flash-max-microamp = <1500000>;
		flash-max-timeout-us = <1280000>;
	};
};

&pm8550_gpios {
	volume_up_n: volume-up-n-state {
		pins = "gpio6";
		function = "normal";
		bias-pull-up;
		input-enable;
		power-source = <1>;
	};
};

&pm8550b_eusb2_repeater {
	qcom,tune-usb2-amplitude = /bits/ 8 <0xc>;
	qcom,tune-usb2-preem = /bits/ 8 <0x7>;
};

&pmk8550_gpios {
	pmk8550_sleep_clk: sleep-clk-state {
		pins = "gpio3";
		function = "func1";
		input-disable;
		output-enable;
		bias-disable;
		power-source = <0>;
	};
};

&pon_resin {
	linux,code = <KEY_VOLUMEDOWN>;

	status = "okay";
};

&q6apmbedai {
	#address-cells = <1>;
	#size-cells = <0>;

	dai@10 {
		reg = <PRIMARY_MI2S_RX>;
		clocks = <&q6prmcc LPASS_CLK_ID_PRI_MI2S_IBIT LPASS_CLK_ATTRIBUTE_COUPLE_NO>;
		clock-names = "bclk";
	};

	dai@11 {
		reg = <PRIMARY_MI2S_TX>;
		clocks = <&q6prmcc LPASS_CLK_ID_PRI_MI2S_IBIT LPASS_CLK_ATTRIBUTE_COUPLE_NO>;
		clock-names = "bclk";
	};
};

&qup_i2c3_data_clk {
	/* Use internal I2C pull-up */
	bias-pull-up = <2200>;
};

&qupv3_id_0 {
	status = "okay";
};

&remoteproc_adsp {
	firmware-name = "adsp.mdt", "adsp_dtb.mdt";

	status = "okay";
};

&remoteproc_cdsp {
	firmware-name = "cdsp.mdt", "cdsp_dtb.mdt";

	status = "okay";
};

&remoteproc_mpss {
	firmware-name = "modem.mdt", "modem_dtb.mdt";

	status = "okay";
};

&slim {
	status = "okay";
};

&slim_ngd1 {
	#address-cells = <2>;
	#size-cells = <0>;

	wcn7850_bt_ifd: ifd@0,0 {
		compatible = "slim217,220";
		reg = <0 0>;
	};

	wcn7850_bt_slim: bt@1,0 {
		compatible = "slim217,220";
		reg = <1 0>;

		slim-ifc-dev = <&wcn7850_bt_ifd>;

		qcom,rx-channels = <157>;
		qcom,tx-channels = <159>;

		#sound-dai-cells = <1>;
	};
};

&slimbam {
	status = "okay";
};

&spi1 {
	#address-cells = <1>;
	#size-cells = <0>;

	status = "okay";

	ese@0 {
		compatible = "st,st54l-ese";
		reg = <0>;

		spi-max-frequency = <1000000>;
		spi-cs-setup-delay-ns = <20000>;
	};
};

&spi4 {
	#address-cells = <1>;
	#size-cells = <0>;

	status = "okay";

	touchscreen@0 {
		compatible = "goodix,gt9916";
		reg = <0>;

		interrupt-parent = <&tlmm>;
		interrupts = <162 IRQ_TYPE_LEVEL_LOW>;

		reset-gpios = <&tlmm 161 GPIO_ACTIVE_LOW>;

		avdd-supply = <&ts_avdd>;
		vddio-supply = <&vreg_l12b_1p8>;

		panel = <&display_panel>;

		spi-max-frequency = <20000000>;

		touchscreen-size-x = <17856>;
		touchscreen-size-y = <39680>;

		pinctrl-0 = <&ts_irq>, <&ts_reset>;
		pinctrl-names = "default";
	};
};

&swr1 {
	#address-cells = <2>;
	#size-cells = <0>;

	status = "okay";

	/* WCD9395 RX */
	wcd_rx: codec@0,4 {
		compatible = "sdw20217010e00";
		reg = <0 4>;

		/*
		 * WCD9395 RX Port 1 (HPH_L/R)      <=> SWR1 Port 1 (HPH_L/R)
		 * WCD9395 RX Port 2 (CLSH)         <=> SWR1 Port 2 (CLSH)
		 * WCD9395 RX Port 3 (COMP_L/R)     <=> SWR1 Port 3 (COMP_L/R)
		 * WCD9395 RX Port 4 (LO)           <=> SWR1 Port 4 (LO)
		 * WCD9395 RX Port 5 (DSD_L/R)      <=> SWR1 Port 5 (DSD_L/R)
		 * WCD9395 RX Port 6 (HIFI_PCM_L/R) <=> SWR1 Port 9 (HIFI_PCM_L/R)
		 */
		qcom,rx-port-mapping = <1 2 3 4 5 9>;
	};
};

&swr2 {
	#address-cells = <2>;
	#size-cells = <0>;

	status = "okay";

	/* WCD9395 TX */
	wcd_tx: codec@0,3 {
		compatible = "sdw20217010e00";
		reg = <0 3>;

		/*
		 * WCD9395 TX Port 1 (ADC1,2,3,4)         <=> SWR2 Port 2 (TX SWR_INPUT 0,1,2,3)
		 * WCD9395 TX Port 2 (ADC3,4 & DMIC0,1)   <=> SWR2 Port 2 (TX SWR_INPUT 0,1,2,3)
		 * WCD9395 TX Port 3 (DMIC0,1,2,3 & MBHC) <=> SWR2 Port 3 (TX SWR_INPUT 4,5,6,7)
		 * WCD9395 TX Port 4 (DMIC4,5,6,7)        <=> SWR2 Port 4 (TX SWR_INPUT 8,9,10,11)
		 */
		qcom,tx-port-mapping = <2 2 3 4>;
	};
};

&tlmm {
	gpio-reserved-ranges = <74 1>;

	bt_default: bt-default-state {
		bt-en-pins {
			pins = "gpio17";
			function = "gpio";
			drive-strength = <16>;
			bias-disable;
		};

		sw-ctrl-pins {
			pins = "gpio18";
			function = "gpio";
			bias-pull-down;
		};
	};

	cam_sensor_mclk1_active: cam-sensor-mclk1-active-state {
		pins = "gpio101";
		function = "cam_mclk";
		drive-strength = <2>;
		bias-disable;
	};

	cam_sensor_mclk1_suspend: cam-sensor-mclk1-suspend-state {
		pins = "gpio101";
		function = "cam_mclk";
		drive-strength = <2>;
		bias-pull-down;
	};

	cam_sensor_mclk2_active: cam-sensor-mclk2-active-state {
		pins = "gpio102";
		function = "cam_aon_mclk2";
		drive-strength = <2>;
		bias-disable;
	};

	cam_sensor_mclk2_suspend: cam-sensor-mclk2-suspend-state {
		pins = "gpio102";
		function = "cam_aon_mclk2";
		drive-strength = <2>;
		bias-pull-down;
	};

	cam_sensor_mclk3_active: cam-sensor-mclk3-active-state {
		pins = "gpio103";
		function = "cam_mclk";
		drive-strength = <2>;
		bias-disable;
	};

	cam_sensor_mclk3_suspend: cam-sensor-mclk3-suspend-state {
		pins = "gpio103";
		function = "cam_mclk";
		drive-strength = <2>;
		bias-pull-down;
	};

	cam_sensor_mclk4_active: cam-sensor-mclk4-active-state {
		pins = "gpio104";
		function = "cam_aon_mclk4";
		drive-strength = <2>;
		bias-disable;
	};

	cam_sensor_mclk4_suspend: cam-sensor-mclk4-suspend-state {
		pins = "gpio104";
		function = "cam_aon_mclk4";
		drive-strength = <2>;
		bias-pull-down;
	};

	cam_sensor_rst1_active: cam-sensor-rst1-active-state {
		pins = "gpio15", "gpio13";
		function = "gpio";
		drive-strength = <2>;
		bias-disable;
	};

	cam_sensor_rst1_suspend: cam-sensor-rst1-suspend-state {
		pins = "gpio15", "gpio13";
		function = "gpio";
		drive-strength = <2>;
		bias-pull-down;
		output-low;
	};

	cam_sensor_rst2_active: cam-sensor-rst2-active-state {
		pins = "gpio3", "gpio2";
		function = "gpio";
		drive-strength = <2>;
		bias-disable;
	};

	cam_sensor_rst2_suspend: cam-sensor-rst2-suspend-state {
		pins = "gpio3", "gpio2";
		function = "gpio";
		drive-strength = <2>;
		bias-pull-down;
		output-low;
	};

	cam_sensor_rst3_active: cam-sensor-rst3-active-state {
		pins = "gpio109", "gpio6";
		function = "gpio";
		drive-strength = <2>;
		bias-disable;
	};

	cam_sensor_rst3_suspend: cam-sensor-rst3-suspend-state {
		pins = "gpio109", "gpio6";
		function = "gpio";
		drive-strength = <2>;
		bias-pull-down;
		output-low;
	};

	cam_sensor_rst4_active: cam-sensor-rst4-active-state {
		pins = "gpio7", "gpio58";
		function = "gpio";
		drive-strength = <2>;
		bias-disable;
	};

	cam_sensor_rst4_suspend: cam-sensor-rst4-suspend-state {
		pins = "gpio7", "gpio58";
		function = "gpio";
		drive-strength = <2>;
		bias-pull-down;
		output-low;
	};

	disp0_reset_n_active: disp0-reset-n-active-state {
		pins = "gpio133";
		function = "gpio";
		drive-strength = <8>;
		bias-disable;
	};

	disp0_reset_n_suspend: disp0-reset-n-suspend-state {
		pins = "gpio133";
		function = "gpio";
		drive-strength = <2>;
		bias-pull-down;
	};

	haptics_int_default: haptics-int-default-state {
		pins = "gpio163";
		function = "gpio";
		drive-strength = <2>;
		bias-pull-up;
	};

	mdp_vsync: mdp-vsync-state {
		pins = "gpio86";
		function = "mdp_vsync";
		drive-strength = <2>;
		bias-pull-down;
	};

	nfc_enable_default: nfc-enable-default-state {
		pins = "gpio34", "gpio35";
		function = "gpio";
		drive-strength = <2>;
		bias-disable;
	};

	nfc_int_default: nfc-int-default-state {
		pins = "gpio75";
		function = "gpio";
		drive-strength = <2>;
		bias-pull-down;
	};

	panel_vddd_en: panel-vddd-en-state {
		pins = "gpio125";
		function = "gpio";
		drive-strength = <2>;
		bias-disable;
	};

	panel_vddio_en: panel-vddio-en-state {
		pins = "gpio14";
		function = "gpio";
		drive-strength = <2>;
		bias-disable;
	};

	ts_avdd_en: ts-avdd-en-state {
		pins = "gpio28";
		function = "gpio";
		drive-strength = <2>;
		bias-disable;
	};

	ts_irq: ts-irq-state {
		pins = "gpio162";
		function = "gpio";
		drive-strength = <8>;
		bias-pull-up;
	};

	ts_reset: ts-reset-state {
		pins = "gpio161";
		function = "gpio";
		drive-strength = <8>;
		bias-pull-up;
	};

	wcd_default: wcd-reset-n-active-state {
		pins = "gpio107";
		function = "gpio";
		drive-strength = <16>;
		bias-disable;
		output-low;
	};

	wlan_en: wlan-en-state {
		pins = "gpio16";
		function = "gpio";
		drive-strength = <8>;
		bias-pull-down;
	};
};

&uart14 {
	status = "okay";

	bluetooth {
		compatible = "qcom,wcn7850-bt";

		vddrfacmn-supply = <&vreg_pmu_rfa_cmn>;
		vddaon-supply = <&vreg_pmu_aon_0p59>;
		vddwlcx-supply = <&vreg_pmu_wlcx_0p8>;
		vddwlmx-supply = <&vreg_pmu_wlmx_0p85>;
		vddrfa0p8-supply = <&vreg_pmu_rfa_0p8>;
		vddrfa1p2-supply = <&vreg_pmu_rfa_1p2>;
		vddrfa1p8-supply = <&vreg_pmu_rfa_1p8>;

		max-speed = <3200000>;
	};
};
